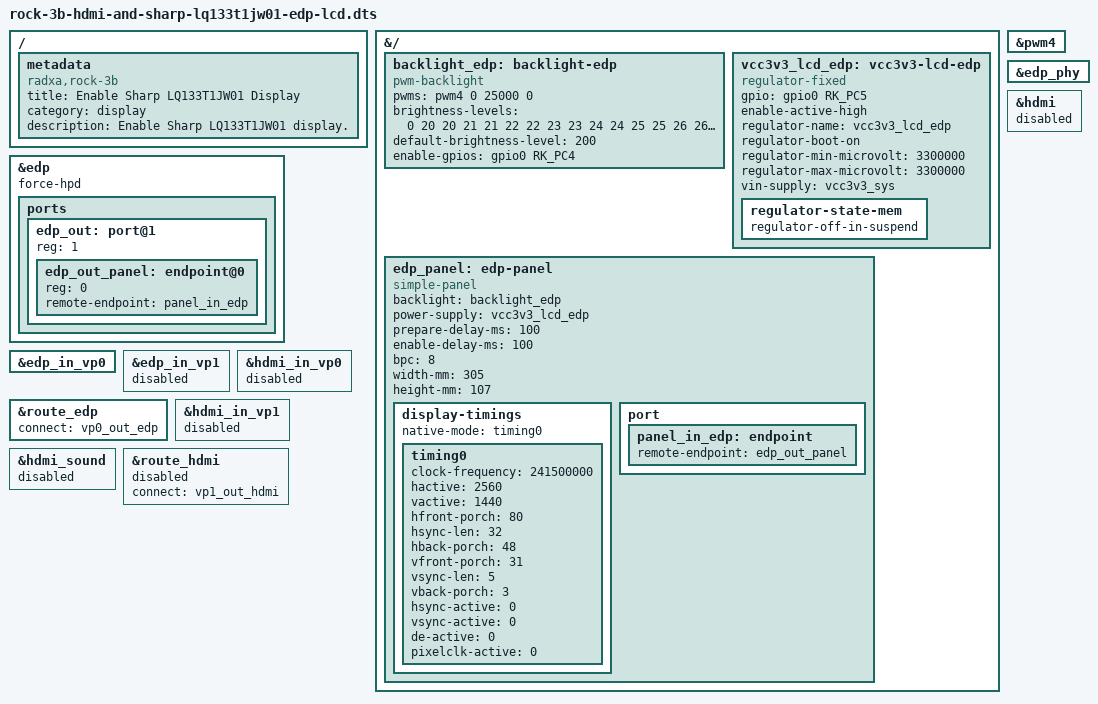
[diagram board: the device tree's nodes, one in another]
/dts-v1/;
/plugin/;

#include <dt-bindings/gpio/gpio.h>
#include <dt-bindings/pinctrl/rockchip.h>
#include <dt-bindings/interrupt-controller/irq.h>

/ {
	metadata {
		title = "Enable Sharp LQ133T1JW01 Display";
		compatible = "radxa,rock-3b";
		category = "display";
		description = "Enable Sharp LQ133T1JW01 display.";
	};
};

&{/} {
	backlight_edp: backlight-edp {
		status = "okay";
		compatible = "pwm-backlight";
		pwms = <&pwm4 0 25000 0>;
		brightness-levels = <
			0  20  20  21  21  22  22  23
			23  24  24  25  25  26  26  27
			27  28  28  29  29  30  30  31
			31  32  32  33  33  34  34  35
			35  36  36  37  37  38  38  39
			40  41  42  43  44  45  46  47
			48  49  50  51  52  53  54  55
			56  57  58  59  60  61  62  63
			64  65  66  67  68  69  70  71
			72  73  74  75  76  77  78  79
			80  81  82  83  84  85  86  87
			88  89  90  91  92  93  94  95
			96  97  98  99 100 101 102 103
			104 105 106 107 108 109 110 111
			112 113 114 115 116 117 118 119
			120 121 122 123 124 125 126 127
			128 129 130 131 132 133 134 135
			136 137 138 139 140 141 142 143
			144 145 146 147 148 149 150 151
			152 153 154 155 156 157 158 159
			160 161 162 163 164 165 166 167
			168 169 170 171 172 173 174 175
			176 177 178 179 180 181 182 183
			184 185 186 187 188 189 190 191
			192 193 194 195 196 197 198 199
			200 201 202 203 204 205 206 207
			208 209 210 211 212 213 214 215
			216 217 218 219 220 221 222 223
			224 225 226 227 228 229 230 231
			232 233 234 235 236 237 238 239
			240 241 242 243 244 245 246 247
			248 249 250 251 252 253 254 255
		>;
		default-brightness-level = <200>;
		enable-gpios = <&gpio0 RK_PC4 GPIO_ACTIVE_HIGH>;
	};

	vcc3v3_lcd_edp: vcc3v3-lcd-edp {
		status = "okay";
		compatible = "regulator-fixed";
		gpio = <&gpio0 RK_PC5 GPIO_ACTIVE_HIGH>;
		enable-active-high;
		regulator-name = "vcc3v3_lcd_edp";
		regulator-boot-on;
		regulator-min-microvolt = <3300000>;
		regulator-max-microvolt = <3300000>;
		vin-supply = <&vcc3v3_sys>;
		regulator-state-mem {
			regulator-off-in-suspend;
		};
	};

	edp_panel: edp-panel {
		status = "okay";
		compatible = "simple-panel";
		backlight = <&backlight_edp>;
		power-supply = <&vcc3v3_lcd_edp>;
		pinctrl-names = "default";
		prepare-delay-ms = <100>;
		enable-delay-ms = <100>;
		bpc = <8>;
		width-mm = <305>;
		height-mm = <107>;
		display-timings {
			native-mode = <&timing0>;
			timing0: timing0 {
				clock-frequency = <241500000>;
				hactive = <2560>;
				vactive = <1440>;
				hfront-porch = <80>;
				hsync-len = <32>;
				hback-porch = <48>;
				vfront-porch = <31>;
				vsync-len = <5>;
				vback-porch = <3>;
				hsync-active = <0>;
				vsync-active = <0>;
				de-active = <0>;
				pixelclk-active = <0>;
			};
		};

		port {
			panel_in_edp: endpoint {
					remote-endpoint = <&edp_out_panel>;
			};
		};
	};
};

&pwm4 {
	status = "okay";
};

&edp {
	force-hpd;
	status = "okay";

	ports {
		#address-cells = <1>;
		#size-cells = <0>;
		edp_out: port@1 {
			reg = <1>;
			#address-cells = <1>;
			#size-cells = <0>;

			edp_out_panel: endpoint@0 {
				reg = <0>;
				remote-endpoint = <&panel_in_edp>;
			};
		};
	};
};

&edp_phy {
	status = "okay";
};

&edp_in_vp0 {
	status = "okay";
};

&edp_in_vp1 {
	status = "disabled";
};

&route_edp {
	status = "okay";
	connect = <&vp0_out_edp>;
};

&hdmi {
	status = "disabled";
};

&hdmi_in_vp0 {
	status = "disabled";
};

&hdmi_in_vp1 {
	status = "disabled";
};

&hdmi_sound {
	status = "disabled";
};

&route_hdmi {
	status = "disabled";
	connect = <&vp1_out_hdmi>;
};
